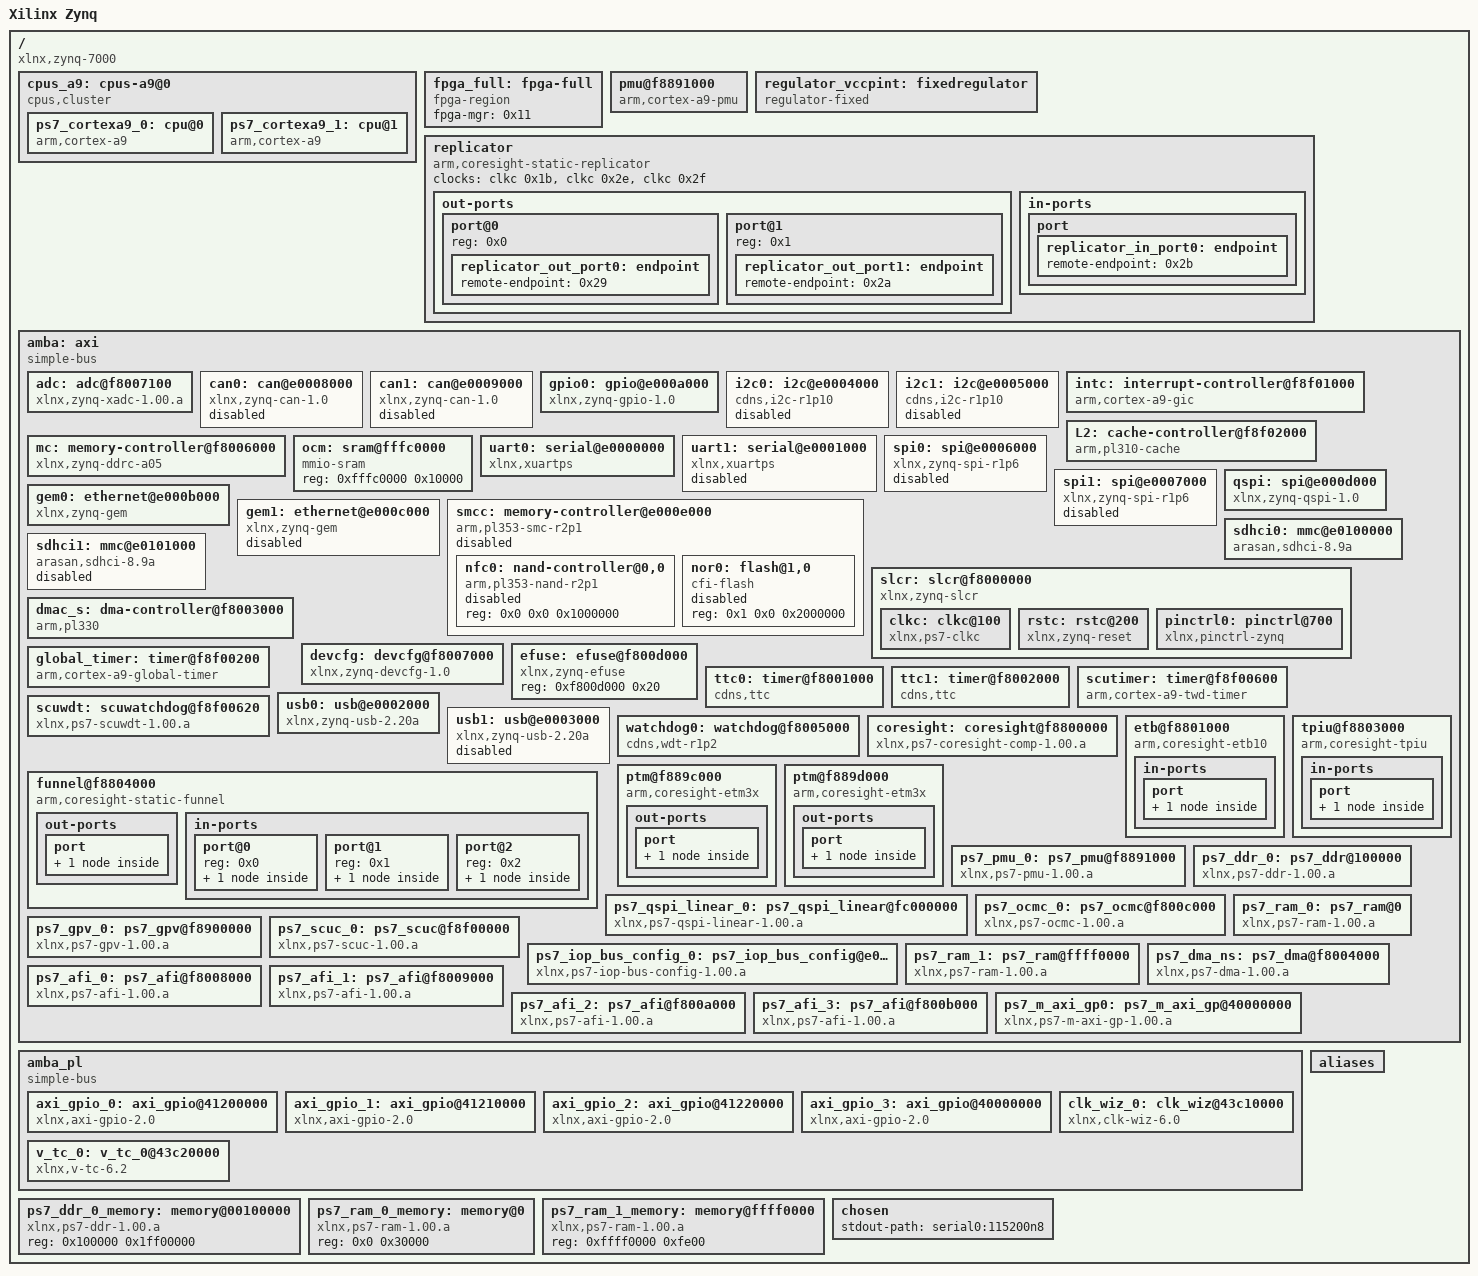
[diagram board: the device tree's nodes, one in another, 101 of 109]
/*
 * Copyright (C) 2011-2022 Xilinx, Inc.
 * Copyright (C) 2022 Advanced Micro Devices, Inc. All Rights Reserved.
 *
 * This software is licensed under the terms of the GNU General Public
 * License version 2, as published by the Free Software Foundation, and
 * may be copied, distributed, and modified under those terms.
 *
 * This program is distributed in the hope that it will be useful,
 * but WITHOUT ANY WARRANTY; without even the implied warranty of
 * MERCHANTABILITY or FITNESS FOR A PARTICULAR PURPOSE.  See the
 * GNU General Public License for more details.
 */

/dts-v1/;

/ {
        #address-cells = <0x1>;
        #size-cells = <0x1>;
        compatible = "xlnx,zynq-7000";
        model = "Xilinx Zynq";
        device_id = "7z020";
        slrcount = <0x1>;

        cpus_a9: cpus-a9@0 {
                #address-cells = <0x1>;
                #size-cells = <0x0>;
                compatible = "cpus,cluster";
                address-map = <0xf0000000 &amba 0xf0000000 0x10000000>,
                 <0x100000 &ps7_ddr_0_memory 0x100000 0x1ff00000>,
                 <0x0 &ps7_ram_0_memory 0x0 0x30000>,
                 <0xffff0000 &ps7_ram_1_memory 0xffff0000 0xfe00>,
                 <0x40000000 &axi_gpio_3 0x40000000 0x10000>,
                 <0x41200000 &axi_gpio_0 0x41200000 0x10000>,
                 <0x41210000 &axi_gpio_1 0x41210000 0x10000>,
                 <0x41220000 &axi_gpio_2 0x41220000 0x10000>,
                 <0x43c10000 &clk_wiz_0 0x43c10000 0x10000>,
                 <0x43c20000 &v_tc_0 0x43c20000 0x10000>,
                 <0xf8008000 &ps7_afi_0 0xf8008000 0x1000>,
                 <0xf8009000 &ps7_afi_1 0xf8009000 0x1000>,
                 <0xf800a000 &ps7_afi_2 0xf800a000 0x1000>,
                 <0xf800b000 &ps7_afi_3 0xf800b000 0x1000>,
                 <0xf8800000 &coresight 0xf8800000 0x100000>,
                 <0xf8006000 &mc 0xf8006000 0x1000>,
                 <0xf8007000 &devcfg 0xf8007000 0x100>,
                 <0xf8004000 &ps7_dma_ns 0xf8004000 0x1000>,
                 <0xf8003000 &dmac_s 0xf8003000 0x1000>,
                 <0xe000b000 &gem0 0xe000b000 0x1000>,
                 <0xf8f00200 &global_timer 0xf8f00200 0x100>,
                 <0xe000a000 &gpio0 0xe000a000 0x1000>,
                 <0xf8900000 &ps7_gpv_0 0xf8900000 0x100000>,
                 <0xf8f01000 &intc 0xf8f01000 0x1000>,
                 <0xe0200000 &ps7_iop_bus_config_0 0xe0200000 0x1000>,
                 <0xf8f02000 &L2 0xf8f02000 0x1000>,
                 <0xf800c000 &ps7_ocmc_0 0xf800c000 0x1000>,
                 <0xf8891000 &ps7_pmu_0 0xf8891000 0x1000>,
                 <0xe000d000 &qspi 0xe000d000 0x1000>,
                 <0xfc000000 &ps7_qspi_linear_0 0xfc000000 0x1000000>,
                 <0xf8f00000 &ps7_scuc_0 0xf8f00000 0xfd>,
                 <0xf8f00600 &scutimer 0xf8f00600 0x20>,
                 <0xf8f00620 &scuwdt 0xf8f00620 0xe0>,
                 <0xe0100000 &sdhci0 0xe0100000 0x1000>,
                 <0xf8000000 &slcr 0xf8000000 0x1000>,
                 <0xe0000000 &uart0 0xe0000000 0x1000>,
                 <0xe0002000 &usb0 0xe0002000 0x1000>,
                 <0xf8007100 &adc 0xf8007100 0x21>;
                #ranges-address-cells = <0x1>;
                #ranges-size-cells = <0x1>;
                phandle = <0x35>;

                ps7_cortexa9_0: cpu@0 {
                        compatible = "arm,cortex-a9";
                        device_type = "cpu";
                        reg = <0x0>;
                        clocks = <&clkc 0x3>;
                        clock-latency = <0x3e8>;
                        cpu0-supply = <0x28>;
                        operating-points = <0xa2c2b 0xf4240 0x51616 0xf4240>;
                        xlnx,rable = <0x0>;
                        xlnx,i-cache-size = <0x8000>;
                        xlnx,d-cache-line-size = <0x14>;
                        xlnx,i-cache-line-size = <0x14>;
                        xlnx,cpu-1x-clk-freq-hz = <0x6750918>;
                        xlnx,ip-name = "ps7_cortexa9";
                        xlnx,num-cores = <0x2>;
                        xlnx,d-cache-size = <0x8000>;
                        xlnx,cpu-clk-freq-hz = <0x26be3680>;
                        bus-handle = <0x1>;
                        phandle = <0x31>;
                };

                ps7_cortexa9_1: cpu@1 {
                        compatible = "arm,cortex-a9";
                        device_type = "cpu";
                        reg = <0x1>;
                        clocks = <&clkc 0x3>;
                        xlnx,rable = <0x0>;
                        xlnx,i-cache-size = <0x8000>;
                        xlnx,d-cache-line-size = <0x14>;
                        xlnx,i-cache-line-size = <0x14>;
                        xlnx,cpu-1x-clk-freq-hz = <0x6750918>;
                        xlnx,ip-name = "ps7_cortexa9";
                        xlnx,d-cache-size = <0x8000>;
                        xlnx,cpu-clk-freq-hz = <0x26be3680>;
                        bus-handle = <0x1>;
                        phandle = <0x33>;
                };
        };

        fpga_full: fpga-full {
                compatible = "fpga-region";
                fpga-mgr = <0x11>;
                #address-cells = <0x1>;
                #size-cells = <0x1>;
                ranges;
                phandle = <0x36>;
        };

        pmu@f8891000 {
                compatible = "arm,cortex-a9-pmu";
                interrupts = <0x0 0x5 0x4 0x0 0x6 0x4>;
                interrupt-parent = <&intc>;
                reg = <0xf8891000 0x1000 0xf8893000 0x1000>;
        };

        regulator_vccpint: fixedregulator {
                compatible = "regulator-fixed";
                regulator-name = "VCCPINT";
                regulator-min-microvolt = <0xf4240>;
                regulator-max-microvolt = <0xf4240>;
                regulator-boot-on;
                regulator-always-on;
                phandle = <0x28>;
        };

        replicator {
                compatible = "arm,coresight-static-replicator";
                clocks = <&clkc 0x1b>,
                 <&clkc 0x2e>,
                 <&clkc 0x2f>;
                clock-names = "apb_pclk", "dbg_trc", "dbg_apb";

                out-ports {
                        #address-cells = <0x1>;
                        #size-cells = <0x0>;
                        /* replicator output ports */

                        port@0 {
                                reg = <0x0>;

                                replicator_out_port0: endpoint {
                                        remote-endpoint = <0x29>;
                                        phandle = <0x2d>;
                                };
                        };

                        port@1 {
                                reg = <0x1>;

                                replicator_out_port1: endpoint {
                                        remote-endpoint = <0x2a>;
                                        phandle = <0x2c>;
                                };
                        };
                };

                in-ports {
                        /* replicator input port */

                        port {

                                replicator_in_port0: endpoint {
                                        remote-endpoint = <0x2b>;
                                        phandle = <0x2e>;
                                };
                        };
                };
        };

        amba: axi {
                u-boot,dm-pre-reloc;
                compatible = "simple-bus";
                #address-cells = <0x1>;
                #size-cells = <0x1>;
                interrupt-parent = <&intc>;
                ranges;
                phandle = <0x1>;

                adc: adc@f8007100 {
                        compatible = "xlnx,zynq-xadc-1.00.a";
                        reg = <0xf8007100 0x20>;
                        interrupts = <0x0 0x7 0x4>;
                        interrupt-parent = <&intc>;
                        clocks = <&clkc 0xc>;
                        xlnx,rable = <0x0>;
                        status = "okay";
                        xlnx,interconnect-s-axi-masters = "ps7_cortexa9_0.M_AXI_DP , & , ps7_cortexa9_1.M_AXI_DP";
                        xlnx,ip-name = "ps7_xadc";
                        xlnx,name = "ps7_xadc_0";
                        phandle = <0x26>;
                };

                can0: can@e0008000 {
                        compatible = "xlnx,zynq-can-1.0";
                        status = "disabled";
                        clocks = <&clkc 0x13>,
                         <&clkc 0x24>;
                        clock-names = "can_clk", "pclk";
                        reg = <0xe0008000 0x1000>;
                        interrupts = <0x0 0x1c 0x4>;
                        interrupt-parent = <&intc>;
                        tx-fifo-depth = <0x40>;
                        rx-fifo-depth = <0x40>;
                        phandle = <0x37>;
                };

                can1: can@e0009000 {
                        compatible = "xlnx,zynq-can-1.0";
                        status = "disabled";
                        clocks = <&clkc 0x14>,
                         <&clkc 0x25>;
                        clock-names = "can_clk", "pclk";
                        reg = <0xe0009000 0x1000>;
                        interrupts = <0x0 0x33 0x4>;
                        interrupt-parent = <&intc>;
                        tx-fifo-depth = <0x40>;
                        rx-fifo-depth = <0x40>;
                        phandle = <0x38>;
                };

                gpio0: gpio@e000a000 {
                        compatible = "xlnx,zynq-gpio-1.0";
                        #gpio-cells = <0x2>;
                        clocks = <&clkc 0x2a>;
                        gpio-controller;
                        interrupt-controller;
                        #interrupt-cells = <0x2>;
                        interrupt-parent = <&intc>;
                        interrupts = <0x0 0x14 0x4>;
                        reg = <0xe000a000 0x1000>;
                        xlnx,rable = <0x0>;
                        xlnx,mio-gpio-mask = <0x5600>;
                        status = "okay";
                        gpio-mask-high = <0x0>;
                        xlnx,interconnect-s-axi-masters = "ps7_cortexa9_0.M_AXI_DP , & , ps7_cortexa9_1.M_AXI_DP";
                        xlnx,emio-gpio-width = <0x40>;
                        xlnx,ip-name = "ps7_gpio";
                        gpio-mask-low = <0x5600>;
                        emio-gpio-width = <0x40>;
                        xlnx,name = "ps7_gpio_0";
                        phandle = <0x16>;
                };

                i2c0: i2c@e0004000 {
                        compatible = "cdns,i2c-r1p10";
                        status = "disabled";
                        clocks = <&clkc 0x26>;
                        clock-frequency = <0x61a80>;
                        interrupt-parent = <&intc>;
                        interrupts = <0x0 0x19 0x4>;
                        reg = <0xe0004000 0x1000>;
                        #address-cells = <0x1>;
                        #size-cells = <0x0>;
                        phandle = <0x39>;
                };

                i2c1: i2c@e0005000 {
                        compatible = "cdns,i2c-r1p10";
                        status = "disabled";
                        clocks = <&clkc 0x27>;
                        clock-frequency = <0x61a80>;
                        interrupt-parent = <&intc>;
                        interrupts = <0x0 0x30 0x4>;
                        reg = <0xe0005000 0x1000>;
                        #address-cells = <0x1>;
                        #size-cells = <0x0>;
                        phandle = <0x3a>;
                };

                intc: interrupt-controller@f8f01000 {
                        compatible = "arm,cortex-a9-gic";
                        #interrupt-cells = <0x3>;
                        interrupt-controller;
                        reg = <0xf8f01000 0x1000 0xf8f00100 0x100>;
                        xlnx,rable = <0x0>;
                        status = "okay";
                        xlnx,ppi-s-axi-baseaddr = <0xf8f01000>;
                        xlnx,irq-f2p-mode = "DIRECT";
                        xlnx,interconnect-s-axi-masters = "ps7_cortexa9_0.M_AXI_DP , & , ps7_cortexa9_1.M_AXI_DP";
                        xlnx,ip-name = "ps7_intc_dist";
                        xlnx,ppi-s-axi-highaddr = <0xf8f01fff>;
                        xlnx,name = "ps7_intc_dist_0";
                        phandle = <0x18>;
                };

                L2: cache-controller@f8f02000 {
                        compatible = "arm,pl310-cache";
                        reg = <0xf8f02000 0x1000>;
                        interrupts = <0x0 0x2 0x4>;
                        arm,data-latency = <0x3 0x2 0x2>;
                        arm,tag-latency = <0x2 0x2 0x2>;
                        cache-unified;
                        cache-level = <0x2>;
                        xlnx,rable = <0x0>;
                        status = "okay";
                        xlnx,interconnect-s-axi-masters = "ps7_cortexa9_0.M_AXI_DP , & , ps7_cortexa9_1.M_AXI_DP";
                        xlnx,ip-name = "ps7_pl310";
                        xlnx,name = "ps7_pl310_0";
                        phandle = <0x1a>;
                };

                mc: memory-controller@f8006000 {
                        compatible = "xlnx,zynq-ddrc-a05";
                        reg = <0xf8006000 0x1000>;
                        xlnx,rable = <0x0>;
                        status = "okay";
                        xlnx,interconnect-s-axi-masters = "ps7_cortexa9_0.M_AXI_DP , & , ps7_cortexa9_1.M_AXI_DP";
                        xlnx,ddr-clk-freq-hz = <0x1f4add40>;
                        xlnx,ip-name = "ps7_ddrc";
                        xlnx,has-ecc = <0x0>;
                        xlnx,name = "ps7_ddrc_0";
                        phandle = <0x10>;
                };

                ocm: sram@fffc0000 {
                        compatible = "mmio-sram";
                        reg = <0xfffc0000 0x10000>;
                        phandle = <0x3b>;
                };

                uart0: serial@e0000000 {
                        compatible = "xlnx,xuartps", "cdns,uart-r1p8";
                        status = "okay";
                        clocks = <&clkc 0x17>,
                         <&clkc 0x28>;
                        clock-names = "uart_clk", "pclk";
                        reg = <0xe0000000 0x1000>;
                        interrupts = <0x0 0x1b 0x4>;
                        interrupt-parent = <&intc>;
                        xlnx,rable = <0x0>;
                        xlnx,clock-freq = <0x5f5e100>;
                        xlnx,interconnect-s-axi-masters = "ps7_cortexa9_0.M_AXI_DP , & , ps7_cortexa9_1.M_AXI_DP";
                        xlnx,has-modem = <0x0>;
                        xlnx,ip-name = "ps7_uart";
                        cts-override;
                        port-number = <0x0>;
                        xlnx,uart-clk-freq-hz = <0x5f5e100>;
                        xlnx,name = "ps7_uart_0";
                        phandle = <0x24>;
                };

                uart1: serial@e0001000 {
                        compatible = "xlnx,xuartps", "cdns,uart-r1p8";
                        status = "disabled";
                        clocks = <&clkc 0x18>,
                         <&clkc 0x29>;
                        clock-names = "uart_clk", "pclk";
                        reg = <0xe0001000 0x1000>;
                        interrupts = <0x0 0x32 0x4>;
                        interrupt-parent = <&intc>;
                        phandle = <0x3c>;
                };

                spi0: spi@e0006000 {
                        compatible = "xlnx,zynq-spi-r1p6";
                        reg = <0xe0006000 0x1000>;
                        status = "disabled";
                        interrupt-parent = <&intc>;
                        interrupts = <0x0 0x1a 0x4>;
                        clocks = <&clkc 0x19>,
                         <&clkc 0x22>;
                        clock-names = "ref_clk", "pclk";
                        #address-cells = <0x1>;
                        #size-cells = <0x0>;
                        phandle = <0x3d>;
                };

                spi1: spi@e0007000 {
                        compatible = "xlnx,zynq-spi-r1p6";
                        reg = <0xe0007000 0x1000>;
                        status = "disabled";
                        interrupt-parent = <&intc>;
                        interrupts = <0x0 0x31 0x4>;
                        clocks = <&clkc 0x1a>,
                         <&clkc 0x23>;
                        clock-names = "ref_clk", "pclk";
                        #address-cells = <0x1>;
                        #size-cells = <0x0>;
                        phandle = <0x3e>;
                };

                qspi: spi@e000d000 {
                        compatible = "xlnx,zynq-qspi-1.0";
                        reg = <0xe000d000 0x1000>;
                        interrupt-parent = <&intc>;
                        interrupts = <0x0 0x13 0x4>;
                        clocks = <&clkc 0xa>,
                         <&clkc 0x2b>;
                        clock-names = "ref_clk", "pclk";
                        status = "okay";
                        #address-cells = <0x1>;
                        #size-cells = <0x0>;
                        xlnx,qspi-clk-freq-hz = <0xbebc200>;
                        xlnx,rable = <0x0>;
                        xlnx,bus-width = <0x2>;
                        xlnx,ip-name = "ps7_qspi";
                        xlnx,interconnect-s-axi-masters = "ps7_cortexa9_0.M_AXI_DP , & , ps7_cortexa9_1.M_AXI_DP";
                        spi-rx-bus-width = <0x4>;
                        xlnx,connection-mode = <0x0>;
                        spi-tx-bus-width = <0x4>;
                        qspi-fbclk = <0x0>;
                        xlnx,clock-freq = <0xbebc200>;
                        xlnx,fb-clk = <0x1>;
                        xlnx,qspi-mode = <0x0>;
                        xlnx,name = "ps7_qspi_0";
                        xlnx,qspi-bus-width = <0x2>;
                        is-dual = <0x0>;
                        phandle = <0x1d>;
                };

                gem0: ethernet@e000b000 {
                        compatible = "xlnx,zynq-gem", "cdns,gem";
                        reg = <0xe000b000 0x1000>;
                        status = "okay";
                        interrupts = <0x0 0x16 0x4>;
                        interrupt-parent = <&intc>;
                        clocks = <&clkc 0x1e>,
                         <&clkc 0x1e>,
                         <&clkc 0xd>;
                        clock-names = "pclk", "hclk", "tx_clk";
                        #address-cells = <0x1>;
                        #size-cells = <0x0>;
                        xlnx,has-mdio = <0x1>;
                        phy-mode = "rgmii-id";
                        xlnx,enet-slcr-1000mbps-div0 = <0x8>;
                        xlnx,enet-slcr-10mbps-div0 = <0x8>;
                        enet-reset = <0x16 0x9 0x0>;
                        xlnx,rable = <0x0>;
                        xlnx,enet-slcr-1000mbps-div1 = <0x1>;
                        xlnx,enet-slcr-10mbps-div1 = <0x32>;
                        xlnx,interconnect-s-axi-masters = "ps7_cortexa9_0.M_AXI_DP , & , ps7_cortexa9_1.M_AXI_DP";
                        xlnx,ip-name = "ps7_ethernet";
                        xlnx,eth-mode = <0x1>;
                        xlnx,enet-reset = "MIO , 9";
                        xlnx,enet-clk-freq-hz = <0x7735940>;
                        xlnx,enet-slcr-100mbps-div0 = <0x8>;
                        xlnx,ptp-enet-clock = <0x6750918>;
                        local-mac-address = [00 0A 23 00 00 00];
                        xlnx,enet-slcr-100mbps-div1 = <0x5>;
                        xlnx,name = "ps7_ethernet_0";
                        phandle = <0x14>;
                };

                gem1: ethernet@e000c000 {
                        compatible = "xlnx,zynq-gem", "cdns,gem";
                        reg = <0xe000c000 0x1000>;
                        status = "disabled";
                        interrupts = <0x0 0x2d 0x4>;
                        interrupt-parent = <&intc>;
                        clocks = <&clkc 0x1f>,
                         <&clkc 0x1f>,
                         <&clkc 0xe>;
                        clock-names = "pclk", "hclk", "tx_clk";
                        #address-cells = <0x1>;
                        #size-cells = <0x0>;
                        phandle = <0x3f>;
                };

                smcc: memory-controller@e000e000 {
                        compatible = "arm,pl353-smc-r2p1", "arm,primecell";
                        reg = <0xe000e000 0x1000>;
                        status = "disabled";
                        clock-names = "memclk", "apb_pclk";
                        clocks = <&clkc 0xb>,
                         <&clkc 0x2c>;
                        ranges = <0x0 0x0 0xe1000000 0x1000000 0x1 0x0 0xe2000000 0x2000000 0x2 0x0 0xe4000000 0x2000000>;
                        /* SRAM/NOR CS1 region */
                        #address-cells = <0x2>;
                        #size-cells = <0x1>;
                        interrupt-parent = <&intc>;
                        interrupts = <0x0 0x12 0x4>;
                        phandle = <0x40>;

                        nfc0: nand-controller@0,0 {
                                compatible = "arm,pl353-nand-r2p1";
                                reg = <0x0 0x0 0x1000000>;
                                status = "disabled";
                                #address-cells = <0x1>;
                                #size-cells = <0x0>;
                                phandle = <0x41>;
                        };

                        nor0: flash@1,0 {
                                status = "disabled";
                                compatible = "cfi-flash";
                                reg = <0x1 0x0 0x2000000>;
                                #address-cells = <0x1>;
                                #size-cells = <0x1>;
                                phandle = <0x42>;
                        };
                };

                sdhci0: mmc@e0100000 {
                        compatible = "arasan,sdhci-8.9a";
                        status = "okay";
                        clock-names = "clk_xin", "clk_ahb";
                        clocks = <&clkc 0x15>,
                         <&clkc 0x20>;
                        interrupt-parent = <&intc>;
                        interrupts = <0x0 0x18 0x4>;
                        reg = <0xe0100000 0x1000>;
                        xlnx,rable = <0x0>;
                        xlnx,has-power = <0x0>;
                        xlnx,interconnect-s-axi-masters = "ps7_cortexa9_0.M_AXI_DP , & , ps7_cortexa9_1.M_AXI_DP";
                        xlnx,ip-name = "ps7_sdio";
                        xlnx,sdio-clk-freq-hz = <0x2faf080>;
                        xlnx,has-wp = <0x0>;
                        xlnx,has-cd = <0x1>;
                        xlnx,name = "ps7_sd_0";
                        phandle = <0x22>;
                };

                sdhci1: mmc@e0101000 {
                        compatible = "arasan,sdhci-8.9a";
                        status = "disabled";
                        clock-names = "clk_xin", "clk_ahb";
                        clocks = <&clkc 0x16>,
                         <&clkc 0x21>;
                        interrupt-parent = <&intc>;
                        interrupts = <0x0 0x2f 0x4>;
                        reg = <0xe0101000 0x1000>;
                        phandle = <0x43>;
                };

                slcr: slcr@f8000000 {
                        u-boot,dm-pre-reloc;
                        #address-cells = <0x1>;
                        #size-cells = <0x1>;
                        compatible = "xlnx,zynq-slcr", "syscon", "simple-mfd";
                        reg = <0xf8000000 0x1000>;
                        ranges;
                        xlnx,rable = <0x0>;
                        status = "okay";
                        xlnx,interconnect-s-axi-masters = "ps7_cortexa9_0.M_AXI_DP , & , ps7_cortexa9_1.M_AXI_DP";
                        xlnx,ip-name = "ps7_slcr";
                        xlnx,name = "ps7_slcr_0";
                        phandle = <0x23>;

                        clkc: clkc@100 {
                                u-boot,dm-pre-reloc;
                                #clock-cells = <0x1>;
                                compatible = "xlnx,ps7-clkc";
                                fclk-enable = <0x3>;
                                clock-output-names = "armpll", "ddrpll", "iopll", "cpu_6or4x", "cpu_3or2x", "cpu_2x", "cpu_1x", "ddr2x", "ddr3x", "dci", "lqspi", "smc", "pcap", "gem0", "gem1", "fclk0", "fclk1", "fclk2", "fclk3", "can0", "can1", "sdio0", "sdio1", "uart0", "uart1", "spi0", "spi1", "dma", "usb0_aper", "usb1_aper", "gem0_aper", "gem1_aper", "sdio0_aper", "sdio1_aper", "spi0_aper", "spi1_aper", "can0_aper", "can1_aper", "i2c0_aper", "i2c1_aper", "uart0_aper", "uart1_aper", "gpio_aper", "lqspi_aper", "smc_aper", "swdt", "dbg_trc", "dbg_apb";
                                reg = <0x100 0x100>;
                                ps-clk-frequency = <0x2faf080>;
                                phandle = <0x27>;
                        };

                        rstc: rstc@200 {
                                compatible = "xlnx,zynq-reset";
                                reg = <0x200 0x48>;
                                #reset-cells = <0x1>;
                                syscon = <0x23>;
                                phandle = <0x44>;
                        };

                        pinctrl0: pinctrl@700 {
                                compatible = "xlnx,pinctrl-zynq";
                                reg = <0x700 0x200>;
                                syscon = <0x23>;
                                phandle = <0x45>;
                        };
                };

                dmac_s: dma-controller@f8003000 {
                        compatible = "arm,pl330", "arm,primecell";
                        reg = <0xf8003000 0x1000>;
                        interrupt-parent = <&intc>;
                        /*
                         * interrupt-names = "abort", "dma0", "dma1", "dma2", "dma3",
                         * "dma4", "dma5", "dma6", "dma7";
                         */
                        interrupts = <0x0 0xd 0x4 0x0 0xe 0x4 0x0 0xf 0x4 0x0 0x10 0x4 0x0 0x11 0x4 0x0 0x28 0x4 0x0 0x29 0x4 0x0 0x2a 0x4 0x0 0x2b 0x4>;
                        #dma-cells = <0x1>;
                        clocks = <&clkc 0x1b>;
                        clock-names = "apb_pclk";
                        xlnx,rable = <0x0>;
                        status = "okay";
                        xlnx,interconnect-s-axi-masters = "ps7_cortexa9_0.M_AXI_DP , & , ps7_cortexa9_1.M_AXI_DP";
                        xlnx,ip-name = "ps7_dma";
                        xlnx,is-secure;
                        xlnx,name = "ps7_dma_s";
                        phandle = <0x13>;
                };

                devcfg: devcfg@f8007000 {
                        compatible = "xlnx,zynq-devcfg-1.0";
                        reg = <0xf8007000 0x100>;
                        interrupt-parent = <&intc>;
                        interrupts = <0x0 0x8 0x4>;
                        clocks = <&clkc 0xc>,
                         <&clkc 0xf>,
                         <&clkc 0x10>,
                         <&clkc 0x11>,
                         <&clkc 0x12>;
                        clock-names = "ref_clk", "fclk0", "fclk1", "fclk2", "fclk3";
                        syscon = <0x23>;
                        xlnx,rable = <0x0>;
                        status = "okay";
                        xlnx,interconnect-s-axi-masters = "ps7_cortexa9_0.M_AXI_DP , & , ps7_cortexa9_1.M_AXI_DP";
                        xlnx,ip-name = "ps7_dev_cfg";
                        xlnx,name = "ps7_dev_cfg_0";
                        phandle = <0x11>;
                };

                efuse: efuse@f800d000 {
                        compatible = "xlnx,zynq-efuse";
                        reg = <0xf800d000 0x20>;
                        phandle = <0x46>;
                };

                global_timer: timer@f8f00200 {
                        compatible = "arm,cortex-a9-global-timer";
                        reg = <0xf8f00200 0x20>;
                        interrupts = <0x1 0xb 0x301>;
                        interrupt-parent = <&intc>;
                        clocks = <&clkc 0x4>;
                        xlnx,rable = <0x0>;
                        status = "okay";
                        xlnx,interconnect-s-axi-masters = "ps7_cortexa9_0.M_AXI_DP , & , ps7_cortexa9_1.M_AXI_DP";
                        xlnx,ip-name = "ps7_globaltimer";
                        xlnx,name = "ps7_globaltimer_0";
                        phandle = <0x15>;
                };

                ttc0: timer@f8001000 {
                        interrupt-parent = <&intc>;
                        interrupts = <0x0 0xa 0x4 0x0 0xb 0x4 0x0 0xc 0x4>;
                        compatible = "cdns,ttc";
                        clocks = <&clkc 0x6>;
                        reg = <0xf8001000 0x1000>;
                        phandle = <0x47>;
                };

                ttc1: timer@f8002000 {
                        interrupt-parent = <&intc>;
                        interrupts = <0x0 0x25 0x4 0x0 0x26 0x4 0x0 0x27 0x4>;
                        compatible = "cdns,ttc";
                        clocks = <&clkc 0x6>;
                        reg = <0xf8002000 0x1000>;
                        phandle = <0x48>;
                };

                scutimer: timer@f8f00600 {
                        interrupt-parent = <&intc>;
                        interrupts = <0x1 0xd 0x301>;
                        compatible = "arm,cortex-a9-twd-timer";
                        reg = <0xf8f00600 0x20>;
                        clocks = <&clkc 0x4>;
                        xlnx,rable = <0x0>;
                        status = "okay";
                        xlnx,interconnect-s-axi-masters = "ps7_cortexa9_0.M_AXI_DP , & , ps7_cortexa9_1.M_AXI_DP";
                        xlnx,ip-name = "ps7_scutimer";
                        xlnx,name = "ps7_scutimer_0";
                        phandle = <0x20>;
                };

                scuwdt: scuwatchdog@f8f00620 {
                        interrupt-parent = <&intc>;
                        interrupts = <0x1 0xe 0x4>;
                        compatible = "xlnx,ps7-scuwdt-1.00.a";
                        reg = <0xf8f00620 0xe0>;
                        xlnx,rable = <0x0>;
                        status = "okay";
                        xlnx,interconnect-s-axi-masters = "ps7_cortexa9_0.M_AXI_DP , & , ps7_cortexa9_1.M_AXI_DP";
                        xlnx,ip-name = "ps7_scuwdt";
                        xlnx,name = "ps7_scuwdt_0";
                        phandle = <0x21>;
                };

                usb0: usb@e0002000 {
                        compatible = "xlnx,zynq-usb-2.20a", "chipidea,usb2";
                        status = "okay";
                        clocks = <&clkc 0x1c>;
                        interrupt-parent = <&intc>;
                        interrupts = <0x0 0x15 0x4>;
                        reg = <0xe0002000 0x1000>;
                        phy_type = "ulpi";
                        xlnx,usb-reset = "MIO , 46";
                        xlnx,rable = <0x0>;
                        xlnx,interconnect-s-axi-masters = "ps7_cortexa9_0.M_AXI_DP , & , ps7_cortexa9_1.M_AXI_DP";
                        xlnx,ip-name = "ps7_usb";
                        usb-reset = <0x16 0x2e 0x0>;
                        xlnx,name = "ps7_usb_0";
                        phandle = <0x25>;
                };

                usb1: usb@e0003000 {
                        compatible = "xlnx,zynq-usb-2.20a", "chipidea,usb2";
                        status = "disabled";
                        clocks = <&clkc 0x1d>;
                        interrupt-parent = <&intc>;
                        interrupts = <0x0 0x2c 0x4>;
                        reg = <0xe0003000 0x1000>;
                        phy_type = "ulpi";
                        phandle = <0x49>;
                };

                watchdog0: watchdog@f8005000 {
                        clocks = <&clkc 0x2d>;
                        compatible = "cdns,wdt-r1p2";
                        interrupt-parent = <&intc>;
                        interrupts = <0x0 0x9 0x1>;
                        reg = <0xf8005000 0x1000>;
                        timeout-sec = <0xa>;
                        phandle = <0x4a>;
                };

                coresight: coresight@f8800000 {
                        compatible = "xlnx,ps7-coresight-comp-1.00.a";
                        status = "okay";
                        reg = <0xf8800000 0x100000>;
                        xlnx,rable = <0x0>;
                        xlnx,interconnect-s-axi-masters = "ps7_cortexa9_0.M_AXI_DP , & , ps7_cortexa9_1.M_AXI_DP";
                        xlnx,ip-name = "ps7_coresight_comp";
                        xlnx,name = "ps7_coresight_comp_0";
                        phandle = <0xf>;
                };

                etb@f8801000 {
                        compatible = "arm,coresight-etb10", "arm,primecell";
                        reg = <0xf8801000 0x1000>;
                        clocks = <&clkc 0x1b>,
                         <&clkc 0x2e>,
                         <&clkc 0x2f>;
                        clock-names = "apb_pclk", "dbg_trc", "dbg_apb";

                        in-ports {

                                port {

                                        etb_in_port: endpoint {
                                                remote-endpoint = <0x2c>;
                                                phandle = <0x2a>;
                                        };
                                };
                        };
                };

                tpiu@f8803000 {
                        compatible = "arm,coresight-tpiu", "arm,primecell";
                        reg = <0xf8803000 0x1000>;
                        clocks = <&clkc 0x1b>,
                         <&clkc 0x2e>,
                         <&clkc 0x2f>;
                        clock-names = "apb_pclk", "dbg_trc", "dbg_apb";

                        in-ports {

                                port {

                                        tpiu_in_port: endpoint {
                                                remote-endpoint = <0x2d>;
                                                phandle = <0x29>;
                                        };
                                };
                        };
                };

                funnel@f8804000 {
                        compatible = "arm,coresight-static-funnel", "arm,primecell";
                        reg = <0xf8804000 0x1000>;
                        clocks = <&clkc 0x1b>,
                         <&clkc 0x2e>,
                         <&clkc 0x2f>;
                        clock-names = "apb_pclk", "dbg_trc", "dbg_apb";
                        /* funnel output ports */

                        out-ports {

                                port {

                                        funnel_out_port: endpoint {
                                                remote-endpoint = <0x2e>;
                                                phandle = <0x2b>;
                                        };
                                };
                        };

                        in-ports {
                                #address-cells = <0x1>;
                                #size-cells = <0x0>;
                                /* funnel input ports */

                                port@0 {
                                        reg = <0x0>;

                                        funnel0_in_port0: endpoint {
                                                remote-endpoint = <0x2f>;
                                                phandle = <0x32>;
                                        };
                                };

                                port@1 {
                                        reg = <0x1>;

                                        funnel0_in_port1: endpoint {
                                                remote-endpoint = <0x30>;
                                                phandle = <0x34>;
                                        };
                                };

                                port@2 {
                                        reg = <0x2>;

                                        funnel0_in_port2: endpoint {
                                                phandle = <0x4b>;
                                        };
                                };
                        };
                };

                ptm@f889c000 {
                        compatible = "arm,coresight-etm3x", "arm,primecell";
                        reg = <0xf889c000 0x1000>;
                        clocks = <&clkc 0x1b>,
                         <&clkc 0x2e>,
                         <&clkc 0x2f>;
                        clock-names = "apb_pclk", "dbg_trc", "dbg_apb";
                        cpu = <0x31>;

                        out-ports {

                                port {

                                        ptm0_out_port: endpoint {
                                                remote-endpoint = <0x32>;
                                                phandle = <0x2f>;
                                        };
                                };
                        };
                };

                ptm@f889d000 {
                        compatible = "arm,coresight-etm3x", "arm,primecell";
                        reg = <0xf889d000 0x1000>;
                        clocks = <&clkc 0x1b>,
                         <&clkc 0x2e>,
                         <&clkc 0x2f>;
                        clock-names = "apb_pclk", "dbg_trc", "dbg_apb";
                        cpu = <0x33>;

                        out-ports {

                                port {

                                        ptm1_out_port: endpoint {
                                                remote-endpoint = <0x34>;
                                                phandle = <0x30>;
                                        };
                                };
                        };
                };

                ps7_pmu_0: ps7_pmu@f8891000 {
                        xlnx,rable = <0x0>;
                        xlnx,pmu1-s-axi-highaddr = <0xf8893fff>;
                        compatible = "xlnx,ps7-pmu-1.00.a";
                        status = "okay";
                        xlnx,ip-name = "ps7_pmu";
                        reg = <0xf8891000 0x1000 0xf8893000 0x1000>;
                        xlnx,pmu1-s-axi-baseaddr = <0xf8893000>;
                        xlnx,name = "ps7_pmu_0";
                        phandle = <0x1c>;
                };

                ps7_qspi_linear_0: ps7_qspi_linear@fc000000 {
                        xlnx,rable = <0x0>;
                        compatible = "xlnx,ps7-qspi-linear-1.00.a";
                        status = "okay";
                        xlnx,interconnect-s-axi-masters = "ps7_cortexa9_0.M_AXI_DP , & , ps7_cortexa9_1.M_AXI_DP";
                        xlnx,ip-name = "ps7_qspi_linear";
                        reg = <0xfc000000 0x1000000>;
                        xlnx,name = "ps7_qspi_linear_0";
                        phandle = <0x1e>;
                };

                ps7_ddr_0: ps7_ddr@100000 {
                        compatible = "xlnx,ps7-ddr-1.00.a";
                        xlnx,s-axi-hp1-baseaddr = <0xfffffff>;
                        xlnx,s-axi-hp3-baseaddr = <0xfffffff>;
                        xlnx,rable = <0x0>;
                        xlnx,ip-name = "ps7_ddr";
                        xlnx,interconnect-s-axi-masters = "ps7_cortexa9_0.M_AXI_DP , & , ps7_cortexa9_1.M_AXI_DP";
                        reg = <0x100000 0x1ff00000>;
                        xlnx,s-axi-hp1-highaddr = <0xfffffff>;
                        xlnx,s-axi-hp3-highaddr = <0xfffffff>;
                        xlnx,s-axi-hp0-baseaddr = <0xfffffff>;
                        xlnx,s-axi-hp2-baseaddr = <0xfffffff>;
                        status = "okay";
                        xlnx,s-axi-hp0-highaddr = <0xfffffff>;
                        xlnx,s-axi-hp2-highaddr = <0xfffffff>;
                        xlnx,name = "ps7_ddr_0";
                        phandle = <0x4c>;
                };

                ps7_ocmc_0: ps7_ocmc@f800c000 {
                        xlnx,rable = <0x0>;
                        compatible = "xlnx,ps7-ocmc-1.00.a";
                        status = "okay";
                        xlnx,interconnect-s-axi-masters = "ps7_cortexa9_0.M_AXI_DP , & , ps7_cortexa9_1.M_AXI_DP";
                        xlnx,ip-name = "ps7_ocmc";
                        reg = <0xf800c000 0x1000>;
                        xlnx,name = "ps7_ocmc_0";
                        phandle = <0x1b>;
                };

                ps7_gpv_0: ps7_gpv@f8900000 {
                        xlnx,rable = <0x0>;
                        compatible = "xlnx,ps7-gpv-1.00.a";
                        status = "okay";
                        xlnx,interconnect-s-axi-masters = "ps7_cortexa9_0.M_AXI_DP , & , ps7_cortexa9_1.M_AXI_DP";
                        xlnx,ip-name = "ps7_gpv";
                        reg = <0xf8900000 0x100000>;
                        xlnx,name = "ps7_gpv_0";
                        phandle = <0x17>;
                };

                ps7_scuc_0: ps7_scuc@f8f00000 {
                        xlnx,rable = <0x0>;
                        compatible = "xlnx,ps7-scuc-1.00.a";
                        status = "okay";
                        xlnx,interconnect-s-axi-masters = "ps7_cortexa9_0.M_AXI_DP , & , ps7_cortexa9_1.M_AXI_DP";
                        xlnx,ip-name = "ps7_scuc";
                        reg = <0xf8f00000 0xfd>;
                        xlnx,name = "ps7_scuc_0";
                        phandle = <0x1f>;
                };

                ps7_iop_bus_config_0: ps7_iop_bus_config@e0200000 {
                        xlnx,rable = <0x0>;
                        compatible = "xlnx,ps7-iop-bus-config-1.00.a";
                        status = "okay";
                        xlnx,interconnect-s-axi-masters = "ps7_cortexa9_0.M_AXI_DP , & , ps7_cortexa9_1.M_AXI_DP";
                        xlnx,ip-name = "ps7_iop_bus_config";
                        reg = <0xe0200000 0x1000>;
                        xlnx,name = "ps7_iop_bus_config_0";
                        phandle = <0x19>;
                };

                ps7_ram_0: ps7_ram@0 {
                        xlnx,rable = <0x0>;
                        compatible = "xlnx,ps7-ram-1.00.a";
                        status = "okay";
                        xlnx,interconnect-s-axi-masters = "ps7_cortexa9_0.M_AXI_DP , & , ps7_cortexa9_1.M_AXI_DP";
                        xlnx,ip-name = "ps7_ram";
                        reg = <0x0 0x30000>;
                        xlnx,name = "ps7_ram_0";
                        phandle = <0x4d>;
                };

                ps7_ram_1: ps7_ram@ffff0000 {
                        xlnx,rable = <0x0>;
                        compatible = "xlnx,ps7-ram-1.00.a";
                        status = "okay";
                        xlnx,interconnect-s-axi-masters = "ps7_cortexa9_0.M_AXI_DP , & , ps7_cortexa9_1.M_AXI_DP";
                        xlnx,ip-name = "ps7_ram";
                        reg = <0xffff0000 0xfe00>;
                        xlnx,name = "ps7_ram_1";
                        phandle = <0x4e>;
                };

                ps7_dma_ns: ps7_dma@f8004000 {
                        xlnx,rable = <0x0>;
                        compatible = "xlnx,ps7-dma-1.00.a";
                        status = "okay";
                        xlnx,interconnect-s-axi-masters = "ps7_cortexa9_0.M_AXI_DP , & , ps7_cortexa9_1.M_AXI_DP";
                        xlnx,ip-name = "ps7_dma";
                        xlnx,is-secure;
                        reg = <0xf8004000 0x1000>;
                        xlnx,name = "ps7_dma_ns";
                        phandle = <0x12>;
                };

                ps7_afi_0: ps7_afi@f8008000 {
                        xlnx,rable = <0x0>;
                        compatible = "xlnx,ps7-afi-1.00.a";
                        status = "okay";
                        xlnx,interconnect-s-axi-masters = "ps7_cortexa9_0.M_AXI_DP , & , ps7_cortexa9_1.M_AXI_DP";
                        xlnx,ip-name = "ps7_afi";
                        reg = <0xf8008000 0x1000>;
                        xlnx,name = "ps7_afi_0";
                        phandle = <0xb>;
                };

                ps7_afi_1: ps7_afi@f8009000 {
                        xlnx,rable = <0x0>;
                        compatible = "xlnx,ps7-afi-1.00.a";
                        status = "okay";
                        xlnx,interconnect-s-axi-masters = "ps7_cortexa9_0.M_AXI_DP , & , ps7_cortexa9_1.M_AXI_DP";
                        xlnx,ip-name = "ps7_afi";
                        reg = <0xf8009000 0x1000>;
                        xlnx,name = "ps7_afi_1";
                        phandle = <0xc>;
                };

                ps7_afi_2: ps7_afi@f800a000 {
                        xlnx,rable = <0x0>;
                        compatible = "xlnx,ps7-afi-1.00.a";
                        status = "okay";
                        xlnx,interconnect-s-axi-masters = "ps7_cortexa9_0.M_AXI_DP , & , ps7_cortexa9_1.M_AXI_DP";
                        xlnx,ip-name = "ps7_afi";
                        reg = <0xf800a000 0x1000>;
                        xlnx,name = "ps7_afi_2";
                        phandle = <0xd>;
                };

                ps7_afi_3: ps7_afi@f800b000 {
                        xlnx,rable = <0x0>;
                        compatible = "xlnx,ps7-afi-1.00.a";
                        status = "okay";
                        xlnx,interconnect-s-axi-masters = "ps7_cortexa9_0.M_AXI_DP , & , ps7_cortexa9_1.M_AXI_DP";
                        xlnx,ip-name = "ps7_afi";
                        reg = <0xf800b000 0x1000>;
                        xlnx,name = "ps7_afi_3";
                        phandle = <0xe>;
                };

                ps7_m_axi_gp0: ps7_m_axi_gp@40000000 {
                        xlnx,rable = <0x0>;
                        compatible = "xlnx,ps7-m-axi-gp-1.00.a";
                        status = "okay";
                        xlnx,interconnect-s-axi-masters = "ps7_cortexa9_0.M_AXI_DP , & , ps7_cortexa9_1.M_AXI_DP";
                        xlnx,ip-name = "ps7_m_axi_gp";
                        reg = <0x40000000 0x40000000>;
                        xlnx,name = "ps7_m_axi_gp0";
                        phandle = <0x4f>;
                };
        };

        amba_pl: amba_pl {
                ranges;
                compatible = "simple-bus";
                #address-cells = <0x1>;
                #size-cells = <0x1>;
                phandle = <0x50>;

                axi_gpio_0: axi_gpio@41200000 {
                        xlnx,gpio-board-interface = "Custom";
                        compatible = "xlnx,axi-gpio-2.0", "xlnx,xps-gpio-1.00.a";
                        xlnx,all-outputs = <0x1>;
                        xlnx,gpio-width = <0x1>;
                        xlnx,rable = <0x0>;
                        xlnx,dout-default = <0x0>;
                        xlnx,is-dual = <0x0>;
                        xlnx,ip-name = "axi_gpio";
                        xlnx,tri-default-2 = <0xffffffff>;
                        reg = <0x41200000 0x10000>;
                        xlnx,all-inputs-2 = <0x0>;
                        clocks = <&clkc 0xf>;
                        xlnx,all-outputs-2 = <0x0>;
                        xlnx,interrupt-present = <0x0>;
                        xlnx,gpio2-board-interface = "Custom";
                        xlnx,edk-iptype = "PERIPHERAL";
                        xlnx,dout-default-2 = <0x0>;
                        xlnx,gpio2-width = <0x20>;
                        status = "okay";
                        clock-names = "s_axi_aclk";
                        xlnx,tri-default = <0xffffffff>;
                        xlnx,name = "axi_gpio_0";
                        xlnx,all-inputs = <0x0>;
                        phandle = <0x6>;
                };

                axi_gpio_1: axi_gpio@41210000 {
                        xlnx,gpio-board-interface = "Custom";
                        compatible = "xlnx,axi-gpio-2.0", "xlnx,xps-gpio-1.00.a";
                        xlnx,all-outputs = <0x0>;
                        xlnx,gpio-width = <0x1>;
                        xlnx,rable = <0x0>;
                        xlnx,dout-default = <0x0>;
                        xlnx,is-dual = <0x0>;
                        xlnx,ip-name = "axi_gpio";
                        xlnx,tri-default-2 = <0xffffffff>;
                        reg = <0x41210000 0x10000>;
                        xlnx,all-inputs-2 = <0x0>;
                        clocks = <&clkc 0xf>;
                        xlnx,all-outputs-2 = <0x0>;
                        xlnx,interrupt-present = <0x0>;
                        xlnx,gpio2-board-interface = "Custom";
                        xlnx,edk-iptype = "PERIPHERAL";
                        xlnx,dout-default-2 = <0x0>;
                        xlnx,gpio2-width = <0x20>;
                        status = "okay";
                        clock-names = "s_axi_aclk";
                        xlnx,tri-default = <0xffffffff>;
                        xlnx,name = "axi_gpio_1";
                        xlnx,all-inputs = <0x1>;
                        phandle = <0x7>;
                };

                axi_gpio_2: axi_gpio@41220000 {
                        xlnx,gpio-board-interface = "Custom";
                        compatible = "xlnx,axi-gpio-2.0", "xlnx,xps-gpio-1.00.a";
                        xlnx,all-outputs = <0x0>;
                        xlnx,gpio-width = <0x1>;
                        xlnx,rable = <0x0>;
                        xlnx,dout-default = <0x0>;
                        xlnx,is-dual = <0x0>;
                        xlnx,ip-name = "axi_gpio";
                        xlnx,tri-default-2 = <0xffffffff>;
                        reg = <0x41220000 0x10000>;
                        xlnx,all-inputs-2 = <0x0>;
                        clocks = <&clkc 0xf>;
                        xlnx,all-outputs-2 = <0x0>;
                        xlnx,interrupt-present = <0x0>;
                        xlnx,gpio2-board-interface = "Custom";
                        xlnx,edk-iptype = "PERIPHERAL";
                        xlnx,dout-default-2 = <0x0>;
                        xlnx,gpio2-width = <0x20>;
                        status = "okay";
                        clock-names = "s_axi_aclk";
                        xlnx,tri-default = <0xffffffff>;
                        xlnx,name = "axi_gpio_2";
                        xlnx,all-inputs = <0x1>;
                        phandle = <0x8>;
                };

                axi_gpio_3: axi_gpio@40000000 {
                        xlnx,gpio-board-interface = "Custom";
                        compatible = "xlnx,axi-gpio-2.0", "xlnx,xps-gpio-1.00.a";
                        xlnx,all-outputs = <0x0>;
                        xlnx,gpio-width = <0x20>;
                        xlnx,rable = <0x0>;
                        xlnx,dout-default = <0x0>;
                        xlnx,is-dual = <0x0>;
                        xlnx,ip-name = "axi_gpio";
                        xlnx,tri-default-2 = <0xffffffff>;
                        reg = <0x40000000 0x10000>;
                        xlnx,all-inputs-2 = <0x0>;
                        clocks = <&clkc 0xf>;
                        xlnx,all-outputs-2 = <0x0>;
                        xlnx,interrupt-present = <0x0>;
                        xlnx,gpio2-board-interface = "Custom";
                        xlnx,edk-iptype = "PERIPHERAL";
                        xlnx,dout-default-2 = <0x0>;
                        xlnx,gpio2-width = <0x20>;
                        status = "okay";
                        clock-names = "s_axi_aclk";
                        xlnx,tri-default = <0xffffffff>;
                        xlnx,name = "axi_gpio_3";
                        xlnx,all-inputs = <0x1>;
                        phandle = <0x5>;
                };

                clk_wiz_0: clk_wiz@43c10000 {
                        xlnx,reset-type = "ACTIVE_HIGH";
                        xlnx,pll-clkout1-divide = <0x1>;
                        xlnx,clk-out1-port = "clk_out1";
                        xlnx,clkout2-phase = <0x0>;
                        xlnx,clkout3-jitter = <0x0>;
                        xlnx,clkout3-drives = "BUFG";
                        reg = <0x43c10000 0x10000>;
                        xlnx,use-min-o-jitter = <0x0>;
                        xlnx,c-component-name = "video_out_pynq_z2_clk_wiz_0_0";
                        xlnx,clkout4-phase-error = <0x0>;
                        xlnx,clkout5-1 = <0x0>;
                        xlnx,clkout5-2 = <0x0>;
                        xlnx,clkout5-out-freq = <0x64>;
                        xlnx,d-max = <0x50>;
                        xlnx,clkout1-phase = <0x0>;
                        xlnx,divide6-auto = <0x13880>;
                        xlnx,clkout1-jitter = <0xea1f4d8>;
                        xlnx,clkfb-in-n-port = "clkfb_in_n";
                        xlnx,clkout2-requested-out-freq = <0x64>;
                        xlnx,use-locked = <0x1>;
                        xlnx,pll-clkout5-duty-cycle = <0x7a120>;
                        xlnx,mmcm-clkout3-use-fine-ps;
                        xlnx,clkout1-drives = "BUFG";
                        xlnx,input-clk-stopped-port = "input_clk_stopped";
                        xlnx,clkout4-duty-cycle = <0x32>;
                        xlnx,divide3-auto = <0x13880>;
                        xlnx,use-dyn-reconfig = <0x1>;
                        xlnx,clkout3-actual-freq = <0x64>;
                        xlnx,clkout6-requested-duty-cycle = <0x32>;
                        xlnx,diff-clk-in1-board-interface = "Custom";
                        xlnx,mmcm-clkout0-duty-cycle = <0x7a120>;
                        xlnx,clkin2-jitter-ps = <0x64>;
                        xlnx,clkout2-1 = <0x0>;
                        xlnx,in-freq-units = "Units_MHz";
                        xlnx,clkout2-2 = <0x0>;
                        xlnx,feedback-source = "FDBK_AUTO";
                        xlnx,clkout5-requested-out-freq = <0x64>;
                        xlnx,name = "clk_wiz_0";
                        xlnx,prim-in-freq = <0x64>;
                        xlnx,mmcm-clkout5-divide = <0x1>;
                        xlnx,clkout3-phase-error = <0x0>;
                        xlnx,clk-in2-board-interface = "Custom";
                        xlnx,clkin1-ui-jitter = <0x2710>;
                        xlnx,use-inclk-switchover = <0x0>;
                        clock-names = "clk_in1", "s_axi_aclk";
                        xlnx,clkout5-duty-cycle = <0x32>;
                        xlnx,use-clkout4-bar = <0x0>;
                        xlnx,mmcm-clkout1-duty-cycle = <0x7a120>;
                        xlnx,mmcm-clkout2-use-fine-ps;
                        xlnx,clkout2-out-freq = <0x64>;
                        xlnx,use-dyn-phase-shift = <0x0>;
                        xlnx,mmcm-clkout3-divide = <0x1>;
                        xlnx,clkout2-actual-freq = <0x64>;
                        xlnx,o-min = <0x1>;
                        xlnx,daddr-port = "daddr";
                        xlnx,precision = <0x1>;
                        xlnx,mmcm-ref-jitter1 = <0x2710>;
                        clock-output-names = "0x43c10000-clk_out1";
                        xlnx,mmcm-ref-jitter2 = <0x2710>;
                        xlnx,pll-notes = "No , notes";
                        xlnx,use-phase-alignment = <0x1>;
                        xlnx,ref-clk-freq = <0x64>;
                        xlnx,clkout7-requested-duty-cycle = <0x32>;
                        xlnx,inclk-sum-row0 = "Input , Clock , Freq , (MHz) , Input , Jitter , (UI)";
                        xlnx,inclk-sum-row1 = "__primary_________100.000____________0.010";
                        xlnx,use-fast-simulation = <0x0>;
                        xlnx,inclk-sum-row2 = "no_secondary_input_clock";
                        xlnx,mmcm-clkout1-divide = <0x1>;
                        xlnx,din-port = "din";
                        xlnx,reset-board-interface = "Custom";
                        xlnx,clkout6-duty-cycle = <0x32>;
                        xlnx,clkout2-phase-error = <0x0>;
                        xlnx,clkout1-requested-duty-cycle = <0x32>;
                        xlnx,vco-max = <0x4b0>;
                        xlnx,use-freq-synth = <0x1>;
                        xlnx,primtype-sel = "AUTO";
                        xlnx,mmcm-clkout2-duty-cycle = <0x7a120>;
                        xlnx,clkout5-used = <0x0>;
                        xlnx,d-min = <0x1>;
                        xlnx,pll-clkfbout-mult = <0x1>;
                        xlnx,mmcm-clkout4-cascade;
                        xlnx,use-clkout1-bar = <0x0>;
                        xlnx,clk-out6-port = "clk_out6";
                        xlnx,clkout2-sequence-number = <0x1>;
                        xlnx,clk-valid-port = "CLK_VALID";
                        xlnx,clkout2-used = <0x0>;
                        xlnx,clkout4-sequence-number = <0x1>;
                        speed-grade = <0x1>;
                        xlnx,psincdec-port = "psincdec";
                        xlnx,mmcm-clkout1-use-fine-ps;
                        xlnx,clk-out3-port = "clk_out3";
                        xlnx,clkout6-sequence-number = <0x1>;
                        xlnx,platform = "UNKNOWN";
                        xlnx,mmcm-clkout6-phase = <0x0>;
                        xlnx,clkout1-actual-freq = <0x64>;
                        xlnx,clkout6-out-freq = <0x64>;
                        xlnx,mmcm-clkin2-period = <0xa>;
                        xlnx,prim-in-jitter = <0x2710>;
                        xlnx,mmcm-clkfbout-mult-f = <0x2367b88>;
                        status = "okay";
                        xlnx,clkout6-1 = <0x0>;
                        xlnx,clkout6-2 = <0x0>;
                        xlnx,clkout7-duty-cycle = <0x32>;
                        xlnx,outclk-sum-row1 = "clk_out1__74.25000______0.000______50.0______245.495____245.344";
                        xlnx,outclk-sum-row2 = "no_CLK_OUT2_output";
                        xlnx,jitter-sel = "No_Jitter";
                        xlnx,outclk-sum-row3 = "no_CLK_OUT3_output";
                        xlnx,mmcm-clkout5-phase = <0x0>;
                        xlnx,mmcm-clkout3-duty-cycle = <0x7a120>;
                        xlnx,outclk-sum-row4 = "no_CLK_OUT4_output";
                        xlnx,clkfb-in-p-port = "clkfb_in_p";
                        xlnx,outclk-sum-row5 = "no_CLK_OUT5_output";
                        xlnx,outclk-sum-row6 = "no_CLK_OUT6_output";
                        xlnx,outclk-sum-row7 = "no_CLK_OUT7_output";
                        xlnx,clkout1-phase-error = <0xe9fa700>;
                        xlnx,divide5-auto = <0x13880>;
                        xlnx,pll-bandwidth = "OPTIMIZED";
                        xlnx,psdone-port = "psdone";
                        xlnx,clkout3-1 = <0x0>;
                        xlnx,clkout3-2 = <0x0>;
                        xlnx,clkout3-requested-out-freq = <0x64>;
                        xlnx,edk-iptype = "PERIPHERAL";
                        xlnx,pll-clkout4-divide = <0x1>;
                        xlnx,pll-clkfbout-phase = <0x0>;
                        xlnx,divide2-auto = <0x13880>;
                        xlnx,override-mmcm = <0x0>;
                        xlnx,clkout6-jitter = <0x0>;
                        xlnx,ss-mode = "CENTER_HIGH";
                        xlnx,mmcm-notes = "None";
                        xlnx,mmcm-clkout0-use-fine-ps;
                        xlnx,clkout6-drives = "BUFG";
                        xlnx,mmcm-clkfbout-use-fine-ps;
                        xlnx,ss-mod-period = <0xfa0>;
                        xlnx,mmcm-clkout4-phase = <0x0>;
                        xlnx,clkout2-requested-duty-cycle = <0x32>;
                        xlnx,clkout0-actual-freq = <0x46cf710>;
                        xlnx,divclk = <0x0>;
                        xlnx,primary-port = "clk_in1";
                        xlnx,mmcm-compensation = "ZHOLD";
                        xlnx,clkout6-requested-out-freq = <0x64>;
                        xlnx,clkout0-1 = <0x0>;
                        xlnx,clkout0-2 = <0x0>;
                        xlnx,clkout2-requested-phase = <0x0>;
                        xlnx,relative-inclk = "REL_PRIMARY";
                        xlnx,pll-clkout2-divide = <0x1>;
                        xlnx,clkout4-requested-phase = <0x0>;
                        xlnx,enable-user-clock0 = <0x0>;
                        xlnx,filter-1 = <0x0>;
                        xlnx,mmcm-clkout4-duty-cycle = <0x7a120>;
                        xlnx,clkout3-out-freq = <0x64>;
                        xlnx,clkout4-jitter = <0x0>;
                        xlnx,clkout6-requested-phase = <0x0>;
                        xlnx,clkoutphy-requested-freq = <0x258>;
                        xlnx,enable-user-clock1 = <0x0>;
                        xlnx,filter-2 = <0x0>;
                        xlnx,ss-mod-freq = <0xfa>;
                        xlnx,mmcm-divclk-divide = <0x4>;
                        xlnx,enable-user-clock2 = <0x0>;
                        xlnx,in-jitter-units = "Units_UI";
                        xlnx,enable-user-clock3 = <0x0>;
                        xlnx,lock-1 = <0x0>;
                        xlnx,clkout4-drives = "BUFG";
                        xlnx,lock-2 = <0x0>;
                        xlnx,den-port = "den";
                        xlnx,lock-3 = <0x0>;
                        xlnx,use-safe-clock-startup = <0x0>;
                        xlnx,mmcm-clkout3-phase = <0x0>;
                        xlnx,dwe-port = "dwe";
                        xlnx,clkfb-out-n-port = "clkfb_out_n";
                        xlnx,use-max-i-jitter = <0x0>;
                        xlnx,drdy-port = "drdy";
                        xlnx,vco-min = <0x258>;
                        xlnx,pll-clkout0-divide = <0x1>;
                        xlnx,clkin1-jitter-ps = <0x64>;
                        xlnx,clk-in-sel-port = "clk_in_sel";
                        xlnx,use-freeze = <0x0>;
                        xlnx,clkout2-jitter = <0x0>;
                        xlnx,enable-pll0 = <0x0>;
                        xlnx,enable-pll1 = <0x0>;
                        xlnx,clkout2-drives = "BUFG";
                        xlnx,use-inclk-stopped = <0x0>;
                        xlnx,use-clkout3-bar = <0x0>;
                        xlnx,use-clk-valid = <0x0>;
                        xlnx,mmcm-clkout2-phase = <0x0>;
                        compatible = "xlnx,clk-wiz-6.0", "xlnx,clocking-wizard";
                        xlnx,reset-port = "reset";
                        xlnx,mmcm-clkout5-duty-cycle = <0x7a120>;
                        xlnx,mmcm-clkout0-divide-f = <0xbebc20>;
                        xlnx,pll-clkout0-duty-cycle = <0x7a120>;
                        xlnx,diff-clk-in2-board-interface = "Custom";
                        xlnx,clkout3-requested-duty-cycle = <0x32>;
                        xlnx,use-status = <0x0>;
                        xlnx,prim-source = "Single_ended_clock_capable_pin";
                        xlnx,clkout7-used = <0x0>;
                        xlnx,use-clkfb-stopped = <0x0>;
                        xlnx,mmcm-clkout1-phase = <0x0>;
                        xlnx,mmcm-clkout6-divide = <0x1>;
                        xlnx,clkout7-out-freq = <0x64>;
                        xlnx,prim-in-timeperiod = <0xa>;
                        xlnx,clkout4-used = <0x0>;
                        xlnx,pll-clkin-period = <0x1>;
                        xlnx,clk-out5-port = "clk_out5";
                        xlnx,psclk-port = "psclk";
                        xlnx,primitive = "MMCM";
                        xlnx,clkout1-used;
                        xlnx,reset-low = <0x0>;
                        xlnx,clk-in1-board-interface = "Custom";
                        xlnx,clk-out2-port = "clk_out2";
                        xlnx,power-down-port = "power_down";
                        xlnx,clkout7-phase-error = <0x0>;
                        xlnx,mmcm-clkout6-duty-cycle = <0x7a120>;
                        xlnx,mmcm-clkout4-divide = <0x1>;
                        xlnx,mmcm-clkfbout-phase = <0x0>;
                        xlnx,mmcm-clkout0-phase = <0x0>;
                        xlnx,pll-clkout1-duty-cycle = <0x7a120>;
                        xlnx,user-clk-freq0 = <0x64>;
                        xlnx,user-clk-freq1 = <0x64>;
                        xlnx,pll-clkout5-phase = <0x0>;
                        xlnx,user-clk-freq2 = <0x64>;
                        xlnx,secondary-in-jitter = <0x2710>;
                        xlnx,user-clk-freq3 = <0x64>;
                        xlnx,use-clock-sequencing = <0x0>;
                        xlnx,secondary-source = "Single_ended_clock_capable_pin";
                        xlnx,cddcdone-port = "cddcdone";
                        xlnx,clkout7-phase = <0x0>;
                        xlnx,psen-port = "psen";
                        xlnx,mmcm-clkout6-use-fine-ps;
                        xlnx,dclk-port = "dclk";
                        xlnx,m-max = <0x40>;
                        xlnx,outclk-sum-row0a = "Output , Output , Phase , Duty , Cycle , Pk-to-Pk , Phase";
                        xlnx,clkout1-requested-out-freq = <0x46cf710>;
                        xlnx,clkout6-actual-freq = <0x64>;
                        xlnx,divide7-auto = <0x13880>;
                        xlnx,outclk-sum-row0b = "Clock , Freq , (MHz) , (degrees) , (%) , Jitter , (ps) , Error , (ps)";
                        xlnx,clkout4-1 = <0x0>;
                        xlnx,locked-port = "locked";
                        xlnx,mmcm-clkout2-divide = <0x1>;
                        xlnx,clkin2-ui-jitter = <0x2710>;
                        xlnx,clkout4-2 = <0x0>;
                        xlnx,enable-clock-monitor = <0x0>;
                        xlnx,ss-mod-time = <0xfa0>;
                        xlnx,auto-primitive = "MMCM";
                        xlnx,divide4-auto = <0x13880>;
                        xlnx,pll-clkout4-phase = <0x0>;
                        xlnx,use-power-down = <0x0>;
                        xlnx,mmcm-startup-wait;
                        xlnx,divide1-auto = <0x1>;
                        xlnx,clkout4-requested-duty-cycle = <0x32>;
                        xlnx,clkout4-requested-out-freq = <0x64>;
                        xlnx,rable = <0x0>;
                        xlnx,optimize-clocking-structure-en = <0x0>;
                        xlnx,clkout4-out-freq = <0x64>;
                        xlnx,clkout6-phase = <0x0>;
                        xlnx,num-out-clks = <0x1>;
                        xlnx,ip-name = "clk_wiz";
                        xlnx,pll-clkout2-duty-cycle = <0x7a120>;
                        xlnx,clkout1-1 = <0x0>;
                        xlnx,clkout1-2 = <0x0>;
                        xlnx,clkout1-duty-cycle = <0x32>;
                        xlnx,pll-divclk-divide = <0x1>;
                        xlnx,clkout6-phase-error = <0x0>;
                        xlnx,dout-port = "dout";
                        xlnx,clkout1-sequence-number = <0x1>;
                        xlnx,pll-clkout3-phase = <0x0>;
                        xlnx,cddcreq-port = "cddcreq";
                        xlnx,clkout7-requested-out-freq = <0x64>;
                        xlnx,use-spread-spectrum = <0x0>;
                        xlnx,clkout3-sequence-number = <0x1>;
                        xlnx,clkout5-sequence-number = <0x1>;
                        xlnx,summary-strings = "empty";
                        xlnx,pll-compensation = "SYSTEM_SYNCHRONOUS";
                        xlnx,clkout5-phase = <0x0>;
                        xlnx,clkout7-sequence-number = <0x1>;
                        xlnx,status-port = "STATUS";
                        xlnx,clkfb-out-p-port = "clkfb_out_p";
                        xlnx,mmcm-clkout5-use-fine-ps;
                        xlnx,clkfb-in-port = "clkfb_in";
                        xlnx,clkout5-actual-freq = <0x64>;
                        xlnx,input-mode = "frequency";
                        xlnx,interface-selection = <0x1>;
                        xlnx,mmcm-bandwidth = "OPTIMIZED";
                        xlnx,calc-done = "empty";
                        xlnx,pll-clkout2-phase = <0x0>;
                        xlnx,has-cddc = <0x0>;
                        xlnx,power-reg = <0x0>;
                        xlnx,mmcm-clkin1-period = <0xa>;
                        xlnx,pll-clkout3-duty-cycle = <0x7a120>;
                        xlnx,clkout2-duty-cycle = <0x32>;
                        xlnx,clkout4-phase = <0x0>;
                        xlnx,pll-clkout5-divide = <0x1>;
                        xlnx,clkout7-jitter = <0x0>;
                        clocks = <&clkc 0xf>,
                         <&clkc 0xf>;
                        xlnx,clkout1-out-freq = <0x46cf710>;
                        xlnx,clkout7-drives = "BUFG";
                        xlnx,clkout5-phase-error = <0x0>;
                        xlnx,pll-clkout1-phase = <0x0>;
                        xlnx,clkout5-requested-duty-cycle = <0x32>;
                        xlnx,clkfb-in-signaling = "SINGLE";
                        xlnx,enable-clkoutphy = <0x0>;
                        xlnx,use-clkout2-bar = <0x0>;
                        xlnx,secondary-port = "clk_in2";
                        xlnx,clkout3-phase = <0x0>;
                        xlnx,pll-clkout3-divide = <0x1>;
                        xlnx,use-reset = <0x1>;
                        xlnx,override-pll = <0x0>;
                        xlnx,clkoutphy-mode = "VCO";
                        xlnx,mmcm-clkout4-use-fine-ps;
                        xlnx,clkout5-jitter = <0x0>;
                        xlnx,clkout6-used = <0x0>;
                        xlnx,m-min = <0x2>;
                        xlnx,mmcm-clock-hold;
                        xlnx,clkfb-stopped-port = "clkfb_stopped";
                        xlnx,clk-out7-port = "clk_out7";
                        xlnx,clkout1-requested-phase = <0x0>;
                        xlnx,clkout4-actual-freq = <0x64>;
                        xlnx,pll-clk-feedback = "CLKFBOUT";
                        xlnx,phaseshift-mode = "WAVEFORM";
                        xlnx,clkfb-out-port = "clkfb_out";
                        xlnx,clkout5-drives = "BUFG";
                        xlnx,o-max = <0x80>;
                        xlnx,clkout3-requested-phase = <0x0>;
                        xlnx,secondary-in-timeperiod = <0xa>;
                        xlnx,pll-clkout4-duty-cycle = <0x7a120>;
                        xlnx,clkout3-used = <0x0>;
                        xlnx,jitter-options = "UI";
                        xlnx,clkout5-requested-phase = <0x0>;
                        xlnx,pll-clkout0-phase = <0x0>;
                        xlnx,clk-out4-port = "clk_out4";
                        xlnx,clkout3-duty-cycle = <0x32>;
                        xlnx,clkout7-requested-phase = <0x0>;
                        xlnx,secondary-in-freq = <0x64>;
                        xlnx,use-min-power = <0x0>;
                        xlnx,clkfbout-1 = <0x0>;
                        #clock-cells = <0x1>;
                        xlnx,pll-ref-jitter = <0x2710>;
                        xlnx,clkfbout-2 = <0x0>;
                        phandle = <0x9>;
                };

                v_tc_0: v_tc_0@43c20000 {
                        xlnx,gen-vsync-en = <0x1>;
                        xlnx,gen-hframe-size = <0x672>;
                        xlnx,num-fsyncs = <0x1>;
                        xlnx,gen-hactive-size = <0x500>;
                        xlnx,gen-video-format = <0x2>;
                        xlnx,gen-f1-vblank-hstart = <0x56e>;
                        xlnx,active-video-detection;
                        xlnx,horizontal-sync-generation;
                        xlnx,gen-vblank-en = <0x1>;
                        xlnx,rable = <0x0>;
                        xlnx,gen-avideo-en = <0x1>;
                        xlnx,ip-name = "v_tc";
                        xlnx,fsync-hstart10 = <0x0>;
                        xlnx,max-pixels = <0x800>;
                        xlnx,gen-fieldid-en = <0x0>;
                        reg = <0x43c20000 0x10000>;
                        xlnx,det-vblank-en = <0x1>;
                        xlnx,fsync-hstart11 = <0x0>;
                        xlnx,fsync-hstart12 = <0x0>;
                        xlnx,gen-interlaced = <0x0>;
                        xlnx,det-avideo-en = <0x1>;
                        xlnx,fsync-hstart13 = <0x0>;
                        xlnx,fsync-hstart14 = <0x0>;
                        xlnx,gen-f0-vblank-hend = <0x56e>;
                        xlnx,fsync-hstart15 = <0x0>;
                        xlnx,det-hsync-en = <0x1>;
                        xlnx,gen-avideo-polarity = <0x1>;
                        xlnx,enable-generation;
                        xlnx,max-lines-per-frame = <0x400>;
                        xlnx,has-axi4-lite = <0x1>;
                        compatible = "xlnx,v-tc-6.2", "xlnx,v-tc-6.1";
                        xlnx,max-clocks-per-line = <0x800>;
                        xlnx,gen-f0-vframe-size = <0x2ee>;
                        xlnx,gen-f0-vblank-hstart = <0x56e>;
                        xlnx,max-lines = <0x400>;
                        xlnx,gen-f0-vsync-vstart = <0x2d4>;
                        xlnx,horizontal-blank-generation;
                        xlnx,gen-hsync-end = <0x596>;
                        xlnx,gen-f0-vsync-hstart = <0x56e>;
                        xlnx,gen-f1-vsync-hend = <0x56e>;
                        xlnx,vertical-blank-detection;
                        xlnx,gen-vsync-polarity = <0x1>;
                        xlnx,fsync-vstart0 = <0x0>;
                        xlnx,gen-hsync-polarity = <0x1>;
                        xlnx,fsync-vstart1 = <0x0>;
                        status = "okay";
                        xlnx,fsync-vstart2 = <0x0>;
                        xlnx,gen-hsync-start = <0x56e>;
                        xlnx,gen-f0-vsync-vend = <0x2d9>;
                        xlnx,fsync-vstart3 = <0x0>;
                        xlnx,vertical-sync-detection;
                        xlnx,frame-syncs = <0x1>;
                        xlnx,fsync-vstart4 = <0x0>;
                        xlnx,gen-vactive-size = <0x2d0>;
                        xlnx,name = "v_tc_0";
                        xlnx,fsync-vstart5 = <0x0>;
                        xlnx,gen-achroma-en = <0x0>;
                        xlnx,fsync-vstart6 = <0x0>;
                        xlnx,fsync-vstart7 = <0x0>;
                        xlnx,det-fieldid-en = <0x0>;
                        xlnx,gen-hsync-en = <0x1>;
                        xlnx,fsync-vstart8 = <0x0>;
                        xlnx,fsync-vstart9 = <0x0>;
                        xlnx,fsync-vstart10 = <0x0>;
                        xlnx,fsync-vstart11 = <0x0>;
                        xlnx,arbitrary-res-en = <0x0>;
                        xlnx,fsync-vstart12 = <0x0>;
                        xlnx,fsync-vstart13 = <0x0>;
                        clocks = <&clk_wiz_0 0x0>,
                         <&clkc 0xf>;
                        xlnx,fsync-vstart14 = <0x0>;
                        xlnx,fsync-vstart15 = <0x0>;
                        xlnx,gen-cparity = <0x0>;
                        xlnx,edk-iptype = "PERIPHERAL";
                        xlnx,vertical-sync-generation;
                        xlnx,gen-f1-vblank-hend = <0x56e>;
                        xlnx,det-vsync-en = <0x1>;
                        xlnx,gen-vblank-polarity = <0x1>;
                        xlnx,fsync-hstart0 = <0x0>;
                        clock-names = "clk", "s_axi_aclk";
                        xlnx,interlace-en = <0x0>;
                        xlnx,gen-auto-switch = <0x0>;
                        xlnx,fsync-hstart1 = <0x0>;
                        xlnx,fsync-hstart2 = <0x0>;
                        xlnx,active-video-generation;
                        xlnx,fsync-hstart3 = <0x0>;
                        xlnx,fsync-hstart4 = <0x0>;
                        xlnx,horizontal-blank-detection;
                        xlnx,fsync-hstart5 = <0x0>;
                        xlnx,gen-f1-vframe-size = <0x2ee>;
                        xlnx,fsync-hstart6 = <0x0>;
                        xlnx,fsync-hstart7 = <0x0>;
                        xlnx,fsync-hstart8 = <0x0>;
                        xlnx,gen-hblank-en = <0x1>;
                        xlnx,fsync-hstart9 = <0x0>;
                        xlnx,horizontal-sync-detection;
                        xlnx,gen-f1-vsync-vend = <0x2d9>;
                        xlnx,detect-en = <0x0>;
                        xlnx,det-hblank-en = <0x1>;
                        xlnx,vid-ppc = <0x4>;
                        xlnx,has-intc-if = <0x0>;
                        xlnx,generate-en = <0x1>;
                        xlnx,gen-achroma-polarity = <0x1>;
                        xlnx,sync-en = <0x0>;
                        xlnx,det-achroma-en = <0x0>;
                        xlnx,generator;
                        xlnx,gen-f1-vsync-vstart = <0x2d4>;
                        xlnx,vertical-blank-generation;
                        xlnx,gen-hblank-polarity = <0x1>;
                        xlnx,video-mode = "720p";
                        xlnx,gen-fieldid-polarity = <0x1>;
                        xlnx,gen-f1-vsync-hstart = <0x56e>;
                        xlnx,gen-f0-vsync-hend = <0x56e>;
                        phandle = <0xa>;
                };
        };

        ps7_ddr_0_memory: memory@00100000 {
                compatible = "xlnx,ps7-ddr-1.00.a";
                device_type = "memory";
                reg = <0x100000 0x1ff00000>;
                phandle = <0x2>;
        };

        ps7_ram_0_memory: memory@0 {
                compatible = "xlnx,ps7-ram-1.00.a";
                device_type = "memory";
                reg = <0x0 0x30000>;
                phandle = <0x3>;
        };

        ps7_ram_1_memory: memory@ffff0000 {
                compatible = "xlnx,ps7-ram-1.00.a";
                device_type = "memory";
                reg = <0xffff0000 0xfe00>;
                phandle = <0x4>;
        };

        chosen {
                stdout-path = "serial0:115200n8";
        };

        aliases {
                serial0 = "/axi/serial@e0000000";
                spi0 = "/axi/spi@e000d000";
                serial1 = "/axi/coresight@f8800000";
                ethernet0 = "/axi/ethernet@e000b000";
        };

        __symbols__ {
                cpus_a9 = "/cpus-a9@0";
                ps7_cortexa9_0 = "/cpus-a9@0/cpu@0";
                ps7_cortexa9_1 = "/cpus-a9@0/cpu@1";
                fpga_full = "/fpga-full";
                regulator_vccpint = "/fixedregulator";
                replicator_out_port0 = "/replicator/out-ports/port@0/endpoint";
                replicator_out_port1 = "/replicator/out-ports/port@1/endpoint";
                replicator_in_port0 = "/replicator/in-ports/port/endpoint";
                amba = "/axi";
                adc = "/axi/adc@f8007100";
                can0 = "/axi/can@e0008000";
                can1 = "/axi/can@e0009000";
                gpio0 = "/axi/gpio@e000a000";
                i2c0 = "/axi/i2c@e0004000";
                i2c1 = "/axi/i2c@e0005000";
                intc = "/axi/interrupt-controller@f8f01000";
                L2 = "/axi/cache-controller@f8f02000";
                mc = "/axi/memory-controller@f8006000";
                ocm = "/axi/sram@fffc0000";
                uart0 = "/axi/serial@e0000000";
                uart1 = "/axi/serial@e0001000";
                spi0 = "/axi/spi@e0006000";
                spi1 = "/axi/spi@e0007000";
                qspi = "/axi/spi@e000d000";
                gem0 = "/axi/ethernet@e000b000";
                gem1 = "/axi/ethernet@e000c000";
                smcc = "/axi/memory-controller@e000e000";
                nfc0 = "/axi/memory-controller@e000e000/nand-controller@0,0";
                nor0 = "/axi/memory-controller@e000e000/flash@1,0";
                sdhci0 = "/axi/mmc@e0100000";
                sdhci1 = "/axi/mmc@e0101000";
                slcr = "/axi/slcr@f8000000";
                clkc = "/axi/slcr@f8000000/clkc@100";
                rstc = "/axi/slcr@f8000000/rstc@200";
                pinctrl0 = "/axi/slcr@f8000000/pinctrl@700";
                dmac_s = "/axi/dma-controller@f8003000";
                devcfg = "/axi/devcfg@f8007000";
                efuse = "/axi/efuse@f800d000";
                global_timer = "/axi/timer@f8f00200";
                ttc0 = "/axi/timer@f8001000";
                ttc1 = "/axi/timer@f8002000";
                scutimer = "/axi/timer@f8f00600";
                scuwdt = "/axi/scuwatchdog@f8f00620";
                usb0 = "/axi/usb@e0002000";
                usb1 = "/axi/usb@e0003000";
                watchdog0 = "/axi/watchdog@f8005000";
                coresight = "/axi/coresight@f8800000";
                etb_in_port = "/axi/etb@f8801000/in-ports/port/endpoint";
                tpiu_in_port = "/axi/tpiu@f8803000/in-ports/port/endpoint";
                funnel_out_port = "/axi/funnel@f8804000/out-ports/port/endpoint";
                funnel0_in_port0 = "/axi/funnel@f8804000/in-ports/port@0/endpoint";
                funnel0_in_port1 = "/axi/funnel@f8804000/in-ports/port@1/endpoint";
                funnel0_in_port2 = "/axi/funnel@f8804000/in-ports/port@2/endpoint";
                ptm0_out_port = "/axi/ptm@f889c000/out-ports/port/endpoint";
                ptm1_out_port = "/axi/ptm@f889d000/out-ports/port/endpoint";
                ps7_pmu_0 = "/axi/ps7_pmu@f8891000";
                ps7_qspi_linear_0 = "/axi/ps7_qspi_linear@fc000000";
                ps7_ddr_0 = "/axi/ps7_ddr@100000";
                ps7_ocmc_0 = "/axi/ps7_ocmc@f800c000";
                ps7_gpv_0 = "/axi/ps7_gpv@f8900000";
                ps7_scuc_0 = "/axi/ps7_scuc@f8f00000";
                ps7_iop_bus_config_0 = "/axi/ps7_iop_bus_config@e0200000";
                ps7_ram_0 = "/axi/ps7_ram@0";
                ps7_ram_1 = "/axi/ps7_ram@ffff0000";
                ps7_dma_ns = "/axi/ps7_dma@f8004000";
                ps7_afi_0 = "/axi/ps7_afi@f8008000";
                ps7_afi_1 = "/axi/ps7_afi@f8009000";
                ps7_afi_2 = "/axi/ps7_afi@f800a000";
                ps7_afi_3 = "/axi/ps7_afi@f800b000";
                ps7_m_axi_gp0 = "/axi/ps7_m_axi_gp@40000000";
                amba_pl = "/amba_pl";
                axi_gpio_0 = "/amba_pl/axi_gpio@41200000";
                axi_gpio_1 = "/amba_pl/axi_gpio@41210000";
                axi_gpio_2 = "/amba_pl/axi_gpio@41220000";
                axi_gpio_3 = "/amba_pl/axi_gpio@40000000";
                clk_wiz_0 = "/amba_pl/clk_wiz@43c10000";
                v_tc_0 = "/amba_pl/v_tc_0@43c20000";
                ps7_ddr_0_memory = "/memory@00100000";
                ps7_ram_0_memory = "/memory@0";
                ps7_ram_1_memory = "/memory@ffff0000";
        };
};
